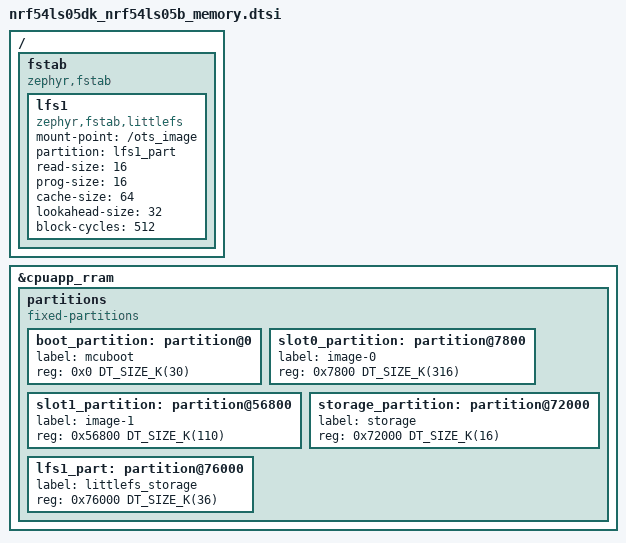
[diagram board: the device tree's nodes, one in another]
/delete-node/ &boot_partition;
/delete-node/ &slot0_partition;
/delete-node/ &slot1_partition;
/delete-node/ &storage_partition;

/ {
	fstab {
		compatible = "zephyr,fstab";
		lfs1: lfs1 {
			compatible = "zephyr,fstab,littlefs";
			mount-point = "/ots_image";
			partition = <&lfs1_part>;
			read-size = <16>;
			prog-size = <16>;
			cache-size = <64>;
			lookahead-size = <32>;
			block-cycles = <512>;
		};
	};
};


&cpuapp_rram {
	partitions {
		compatible = "fixed-partitions";
		#address-cells = <1>;
		#size-cells = <1>;
		boot_partition: partition@0 {
			label = "mcuboot";
			reg = <0x0 DT_SIZE_K(30)>;
		};
		slot0_partition: partition@7800 {
			label = "image-0";
			reg = <0x7800 DT_SIZE_K(316)>;
		};
		slot1_partition: partition@56800 {
			label = "image-1";
			reg = <0x56800 DT_SIZE_K(110)>;
		};
		storage_partition: partition@72000 {
			label = "storage";
			reg = <0x72000 DT_SIZE_K(16)>;
		};
		lfs1_part: partition@76000 {
			label = "littlefs_storage";
			reg = <0x76000 DT_SIZE_K(36)>;
		};
	};
};
